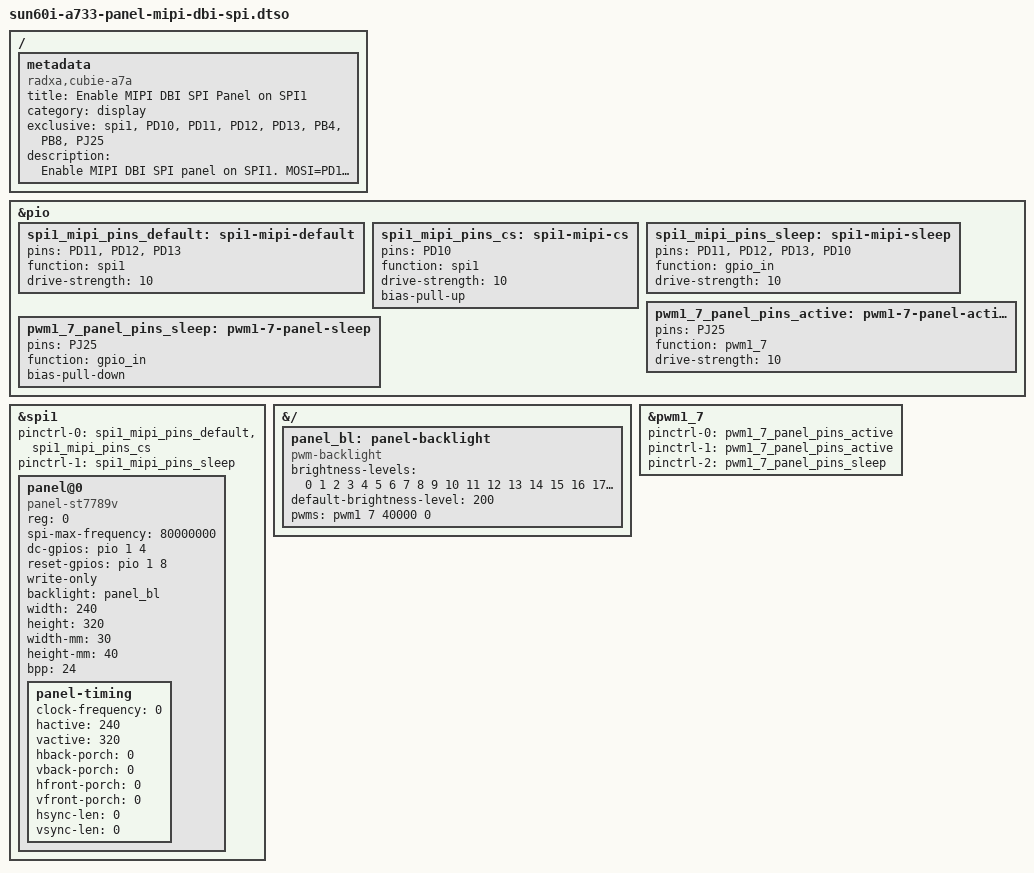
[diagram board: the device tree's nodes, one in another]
// SPDX-License-Identifier: (GPL-2.0+ or MIT)
// Overlay: MIPI DBI SPI Panel on SPI1 with PWM backlight
//
// Uses panel-mipi-dbi-spi driver (drivers/gpu/drm/tiny/).

//
// Init commands loaded from firmware: /lib/firmware/panel-mipi-dbi-spi.bin
// or compatible strings you named
// for example:
// compatible = "panel-st7789v", "panel-mipi-dbi-spi";
// it will load panel-st7789v.bin under /lib/firmware

//
// Wiring:
//   SPI1 MOSI  = PD11 (pin 19)
//   SPI1 CLK   = PD12 (pin 23)
//   SPI1 MISO  = PD13 (pin 21)
//   SPI1 CS0   = PD10 (pin 24)
//   DC         = PB4  (pin 36)
//   RESET      = PB8  (pin 37)
//   BACKLIGHT  = PJ25 (pin 18)  – pwm1_7 pwm-backlight
//
// Drivers: modprobe panel-mipi-dbi
// Firmware: /lib/firmware/panel-mipi-dbi-spi.bin

/dts-v1/;
/plugin/;
#include <dt-bindings/gpio/gpio.h>

/ {
	metadata {
		title = "Enable MIPI DBI SPI Panel on SPI1";
		compatible = "radxa,cubie-a7a", "radxa,cubie-a7z", "radxa,cubie-a7s";
		category = "display";
		exclusive = "spi1", "PD10", "PD11", "PD12", "PD13", "PB4", "PB8", "PJ25";
		description = "Enable MIPI DBI SPI panel on SPI1.
			       	MOSI=PD11(pin19) CLK=PD12(pin23) MISO=PD13(pin21) CS=PD10(pin24)
			       	DC=PB4(pin36) RST=PB8(pin37) BL=PJ25(pin18,pwm1_7).
			       	Firmware: /lib/firmware/panel-mipi-dbi-spi.bin
				Load: sudo modprobe panel-mipi-dbi";
	};
};

/* SPI1 pinmux */
&pio {
	spi1_mipi_pins_default: spi1-mipi-default {
		pins = "PD11", "PD12", "PD13";
		function = "spi1";
		drive-strength = <10>;
	};

	spi1_mipi_pins_cs: spi1-mipi-cs {
		pins = "PD10";
		function = "spi1";
		drive-strength = <10>;
		bias-pull-up;
	};

	spi1_mipi_pins_sleep: spi1-mipi-sleep {
		pins = "PD11", "PD12", "PD13", "PD10";
		function = "gpio_in";
		drive-strength = <10>;
	};
};

/* SPI1 with MIPI DBI panel */
&spi1 {
	pinctrl-names = "default", "sleep";
	pinctrl-0 = <&spi1_mipi_pins_default &spi1_mipi_pins_cs>;
	pinctrl-1 = <&spi1_mipi_pins_sleep>;
	status = "okay";

	panel@0 {
		compatible = "panel-st7789v", "panel-mipi-dbi-spi";
		reg = <0>;
		spi-max-frequency = <80000000>;

		dc-gpios = <&pio 1 4 GPIO_ACTIVE_HIGH>;       /* PB4 */
		reset-gpios = <&pio 1 8 GPIO_ACTIVE_HIGH>;    /* PB8 */

		write-only;
		backlight = <&panel_bl>;

		width  = <240>;
		height = <320>;
		width-mm  = <30>;
		height-mm = <40>;

		bpp = <24>;

		panel-timing {
			clock-frequency = <0>;
			hactive         = <240>;
			vactive         = <320>;
			hback-porch     = <0>;
			vback-porch     = <0>;   /* glass offset: panel starts at row 40 */
			hfront-porch    = <0>;
			vfront-porch    = <0>;
			hsync-len       = <0>;
			vsync-len       = <0>;
		};
	};
};

/* PWM backlight on pwm1_7 / PJ25 */
&{/} {
	panel_bl: panel-backlight {
		compatible = "pwm-backlight";
		status = "okay";

		brightness-levels = <
			  0   1   2   3   4   5   6   7
			  8   9  10  11  12  13  14  15
			 16  17  18  19  20  21  22  23
			 24  25  26  27  28  29  30  31
			 32  33  34  35  36  37  38  39
			 40  41  42  43  44  45  46  47
			 48  49  50  51  52  53  54  55
			 56  57  58  59  60  61  62  63
			 64  65  66  67  68  69  70  71
			 72  73  74  75  76  77  78  79
			 80  81  82  83  84  85  86  87
			 88  89  90  91  92  93  94  95
			 96  97  98  99 100 101 102 103
			104 105 106 107 108 109 110 111
			112 113 114 115 116 117 118 119
			120 121 122 123 124 125 126 127
			128 129 130 131 132 133 134 135
			136 137 138 139 140 141 142 143
			144 145 146 147 148 149 150 151
			152 153 154 155 156 157 158 159
			160 161 162 163 164 165 166 167
			168 169 170 171 172 173 174 175
			176 177 178 179 180 181 182 183
			184 185 186 187 188 189 190 191
			192 193 194 195 196 197 198 199
			200 201 202 203 204 205 206 207
			208 209 210 211 212 213 214 215
			216 217 218 219 220 221 222 223
			224 225 226 227 228 229 230 231
			232 233 234 235 236 237 238 239
			240 241 242 243 244 245 246 247
			248 249 250 251 252 253 254 255>;

		default-brightness-level = <200>;
		pwms = <&pwm1 7 40000 0>;
	};
};

/* PJ25 pinmux for pwm1_7 (with default state for pinctrl fix) */
&pio {
	pwm1_7_panel_pins_active: pwm1-7-panel-active {
		pins = "PJ25";
		function = "pwm1_7";
		drive-strength = <10>;
	};

	pwm1_7_panel_pins_sleep: pwm1-7-panel-sleep {
		pins = "PJ25";
		function = "gpio_in";
		bias-pull-down;
	};
};

&pwm1_7 {
	pinctrl-names = "default", "active", "sleep";
	pinctrl-0 = <&pwm1_7_panel_pins_active>;
	pinctrl-1 = <&pwm1_7_panel_pins_active>;
	pinctrl-2 = <&pwm1_7_panel_pins_sleep>;
	status = "okay";
};
